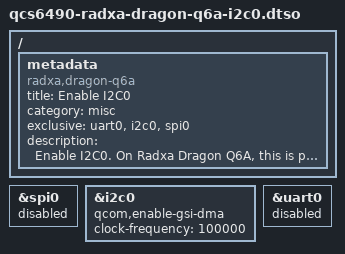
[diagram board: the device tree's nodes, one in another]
// SPDX-License-Identifier: BSD-3-Clause
/*
 * Copyright (c) 2025 Radxa Computer (Shenzhen) Co., Ltd.
 */

/dts-v1/;
/plugin/;

/ {
	metadata {
		title = "Enable I2C0";
		compatible = "radxa,dragon-q6a";
		category = "misc";
		exclusive = "uart0","i2c0","spi0";
		description = "Enable I2C0. 
On Radxa Dragon Q6A, this is pin 15(scl), 13(sda).";
	};
};

&spi0 {
	status = "disabled";
};

&i2c0 {
	qcom,enable-gsi-dma;
	status = "okay";

	clock-frequency = <100000>;
};

&uart0 {
	status = "disabled";
};
